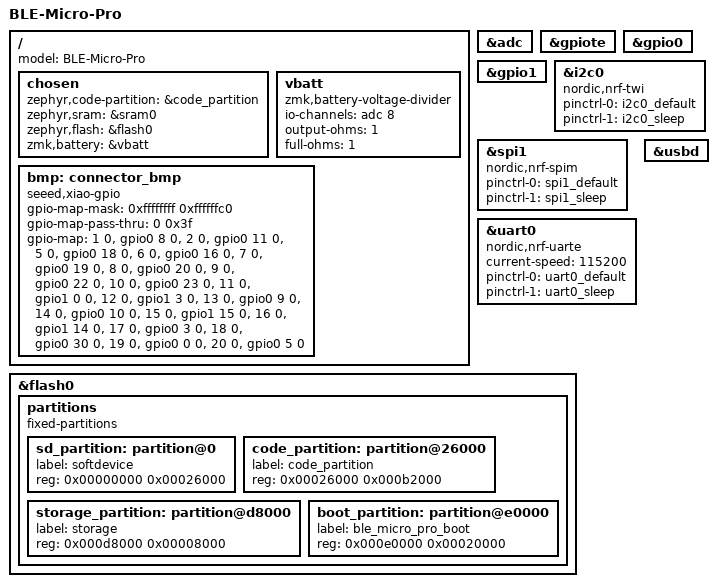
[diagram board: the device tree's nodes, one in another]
/*
 * Copyright (c) 2021 The ZMK Contributors
 *
 * SPDX-License-Identifier: MIT
 */

/dts-v1/;

#include <nordic/nrf52840_qiaa.dtsi>
#include "ble_micro_pro-pinctrl.dtsi"
#include "arduino_pro_micro_pins.dtsi"

/ {
	model = "BLE-Micro-Pro";

	chosen {
		zephyr,code-partition = &code_partition;
		zephyr,sram = &sram0;
		zephyr,flash = &flash0;
        zmk,battery = &vbatt;
	};

    vbatt: vbatt {
        compatible = "zmk,battery-voltage-divider";
        io-channels = <&adc 8>; 
        output-ohms = <1>;
        full-ohms = <1>;
    };

	bmp: connector_bmp {
		compatible = "seeed,xiao-gpio";
		#gpio-cells = <2>;
		gpio-map-mask = <0xffffffff 0xffffffc0>;
		gpio-map-pass-thru = <0 0x3f>;
		gpio-map
			= <1 0 &gpio0 8 0>
			, <2 0 &gpio0 11 0>
			, <5 0 &gpio0 18 0>
			, <6 0 &gpio0 16 0>
			, <7 0 &gpio0 19 0>
			, <8 0 &gpio0 20 0>
			, <9 0 &gpio0 22 0>
			, <10 0 &gpio0 23 0>
			, <11 0 &gpio1 0 0>
			, <12 0 &gpio1 3 0>
			, <13 0 &gpio0 9 0>
			, <14 0 &gpio0 10 0>
			, <15 0 &gpio1 15 0>
			, <16 0 &gpio1 14 0>
			, <17 0 &gpio0 3 0>
			, <18 0 &gpio0 30 0>
			, <19 0 &gpio0 0 0>
			, <20 0 &gpio0 5 0>
			;
	};
};


&adc {
	status = "okay";
};

&gpiote {
	status = "okay";
};

&gpio0 {
	status = "okay";
};

&gpio1 {
	status = "okay";
};

&i2c0 {
    compatible = "nordic,nrf-twi";
    pinctrl-0 = <&i2c0_default>;
    pinctrl-1 = <&i2c0_sleep>;
    pinctrl-names = "default", "sleep";
};

&spi1 {
    compatible = "nordic,nrf-spim";
    pinctrl-0 = <&spi1_default>;
    pinctrl-1 = <&spi1_sleep>;
    pinctrl-names = "default", "sleep";
};

&uart0 {
    compatible = "nordic,nrf-uarte";
    current-speed = <115200>;
    pinctrl-0 = <&uart0_default>;
    pinctrl-1 = <&uart0_sleep>;
    pinctrl-names = "default", "sleep";
};

zephyr_udc0: &usbd {
    status = "okay";
};


&flash0 {
	/*
	 * For more information, see:
	 * http://docs.zephyrproject.org/latest/devices/dts/flash_partitions.html
	 */
	partitions {
		compatible = "fixed-partitions";
		#address-cells = <1>;
		#size-cells = <1>;

		sd_partition: partition@0 {
			label = "softdevice";
			reg = <0x00000000 0x00026000>;
		};
		code_partition: partition@26000 {
			label = "code_partition";
			reg = <0x00026000 0x000b2000>;
		};

		/*
		 * The flash starting at 0x000ec000 and ending at
		 * 0x000f3fff is reserved for use by the application.
		 */

		/*
		 * Storage partition will be used by FCB/LittleFS/NVS
		 * if enabled.
		 */
		storage_partition: partition@d8000 {
			label = "storage";
			reg = <0x000d8000 0x00008000>;
		};

		boot_partition: partition@e0000 {
			label = "ble_micro_pro_boot";
			reg = <0x000e0000 0x00020000>;
		};
	};
};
